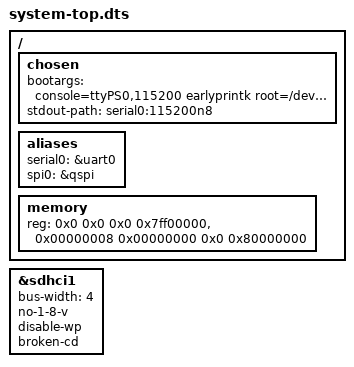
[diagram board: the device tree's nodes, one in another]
/*
 * CAUTION: This file is automatically generated by Xilinx.
 * Version: XSCT 2022.2
 * Today is: Mon Nov 24 10:42:22 2025
 */


/dts-v1/;
#include "zynqmp.dtsi"
#include "zynqmp-clk-ccf.dtsi"
#include "pcw.dtsi"
/ {
	chosen {
		bootargs = "console=ttyPS0,115200 earlyprintk root=/dev/mmcblk0p2 rw rootwait user_debug=1";
		stdout-path = "serial0:115200n8";
	};
	aliases {
		serial0 = &uart0;
		spi0 = &qspi;
	};
	memory {
		device_type = "memory";
		reg = <0x0 0x0 0x0 0x7ff00000>, <0x00000008 0x00000000 0x0 0x80000000>;
	};
};

&sdhci1 {
	status = "okay";
	bus-width = <4>;
	no-1-8-v;
	disable-wp;
	broken-cd;
};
